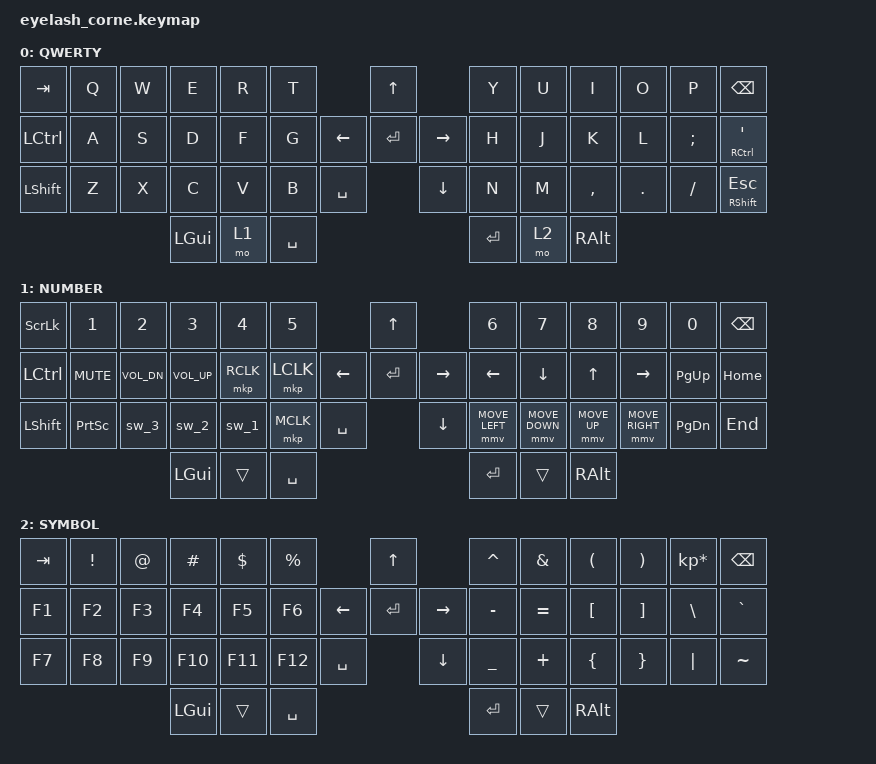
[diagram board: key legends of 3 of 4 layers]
#define ZMK_POINTING_DEFAULT_MOVE_VAL 1200  // 600
#define ZMK_POINTING_DEFAULT_SCRL_VAL 25   // 10

#include <input/processors.dtsi>
#include <zephyr/dt-bindings/input/input-event-codes.h>
#include <behaviors.dtsi>
#include <dt-bindings/zmk/bt.h>
#include <dt-bindings/zmk/ext_power.h>
#include <dt-bindings/zmk/keys.h>
#include <dt-bindings/zmk/outputs.h>
#include <dt-bindings/zmk/pointing.h>
#include <dt-bindings/zmk/rgb.h>

&mmv_input_listener { input-processors = <&zip_xy_scaler 2 1>; };

&msc_input_listener { input-processors = <&zip_scroll_scaler 2 1>; };

&msc {
    acceleration-exponent = <1>;      // 0
    time-to-max-speed-ms = <100>;       // 300
    delay-ms = <0>;                   // 0
};

&mmv {
    time-to-max-speed-ms = <500>;
    acceleration-exponent = <1>;
    trigger-period-ms = <16>;
};


/ {

    macros {
        sw_1: sw_1 {
            compatible = "zmk,behavior-macro";
            label = "SW_1";
             #binding-cells = <0>;
             wait-ms = <40>;
             tap-ms = <40>;
            bindings =
                  <&macro_press &kp LGUI>
                , <&macro_tap &kp SPACE>
                , <&macro_release &kp LGUI>
                , <&macro_tap &kp SEMI>
                , <&macro_press &kp LGUI>
                , <&macro_tap &kp SPACE>
                , <&macro_release &kp LGUI>
                ;
        };

        sw_2: sw_2 {
            compatible = "zmk,behavior-macro";
            label = "SW_2";
             #binding-cells = <0>;
             wait-ms = <40>;
             tap-ms = <40>;
            bindings =
                  <&macro_press &kp LGUI>
                , <&macro_tap &kp SPACE>
                , <&macro_release &kp LGUI>
                , <&macro_tap &kp SQT>
                , <&macro_press &kp LGUI>
                , <&macro_tap &kp SPACE>
                , <&macro_release &kp LGUI>
                ;
        };

        sw_3: sw_3 {
            compatible = "zmk,behavior-macro";
            label = "SW_3";
             #binding-cells = <0>;
             wait-ms = <40>;
             tap-ms = <40>;
            bindings =
                  <&macro_press &kp LGUI>
                , <&macro_tap &kp SPACE>
                , <&macro_release &kp LGUI>
                , <&macro_tap &kp LBKT> 
                , <&macro_press &kp LGUI>
                , <&macro_tap &kp SPACE>
                , <&macro_release &kp LGUI>
                ;
        };
        
    };
    behaviors {
        td0: td0 {
            compatible = "zmk,behavior-tap-dance";
            display-name = "Shift/Caps Lock Tap Dance";
            #binding-cells = <0>;
            bindings = <&kp LEFT_SHIFT>, <&kp CAPS>;
        };
    };

    rgb_encoder: rgb_encoder {
        compatible = "zmk,behavior-sensor-rotate";
        #sensor-binding-cells = <0>;
        bindings = <&rgb_ug RGB_BRI>, <&rgb_ug RGB_BRD>;
    };

    scroll_encoder: scroll_encoder {
        compatible = "zmk,behavior-sensor-rotate";
        #sensor-binding-cells = <0>;
        bindings = <&msc SCRL_DOWN>, <&msc SCRL_UP>;
        tap-ms = <100>;
    };

    keymap {
        compatible = "zmk,keymap";

        default_layer {
            display-name = "QWERTY";
            bindings = <
&kp TAB    &kp Q  &kp W      &kp E     &kp R  &kp T                              &kp UP                &kp Y        &kp U  &kp I      &kp O    &kp P     &kp BSPC
&kp LCTRL  &kp A  &kp S      &kp D     &kp F  &kp G                    &kp LEFT  &kp ENTER  &kp RIGHT  &kp H        &kp J  &kp K      &kp L    &kp SEMI  &mt RCTRL SQT 
&kp LSHFT  &kp Z  &kp X      &kp C     &kp V  &kp B       &kp SPACE              &kp DOWN              &kp N        &kp M  &kp COMMA  &kp DOT  &kp FSLH  &mt RSHIFT ESCAPE
                             &kp LGUI  &mo 1  &kp SPACE                                                &kp RET  &mo 2  &kp RALT
            >;
            sensor-bindings = <&inc_dec_kp C_VOLUME_UP C_VOLUME_DOWN>;
        };

        lower_layer {
            display-name = "NUMBER";
            bindings = <
   &kp SLCK   &kp N1      &kp N2        &kp N3        &kp N4       &kp N5                               &kp UP                   &kp N6           &kp N7          &kp N8        &kp N9           &kp N0         &kp BSPC
   &kp LCTRL  &kp C_MUTE  &kp C_VOL_DN  &kp C_VOL_UP  &mkp RCLK    &mkp LCLK                  &kp LEFT  &kp ENTER  &kp RIGHT     &kp LEFT         &kp DOWN        &kp UP        &kp RIGHT        &kp PAGE_UP    &kp HOME
   &kp LSHFT  &kp PSCRN   &sw_3         &sw_2         &sw_1        &mkp MCLK    &kp SPACE               &kp DOWN                 &mmv MOVE_LEFT   &mmv MOVE_DOWN  &mmv MOVE_UP  &mmv MOVE_RIGHT  &kp PAGE_DOWN  &kp END
                          	            &kp LGUI      &trans       &kp SPACE                                                     &kp RET  &trans  &kp RALT
            >;
            sensor-bindings = <&scroll_encoder>;
        };

        raise_layer {
            display-name = "SYMBOL";
            bindings = <
   &kp  TAB  &kp EXCL &kp AT   &kp HASH  &kp DLLR  &kp PRCNT                          &kp UP                 &kp CARET &kp AMPS  &kp LPAR   &kp RPAR &kp KP_MULTIPLY &kp BSPC
   &kp F1    &kp F2    &kp F3  &kp F4    &kp F5    &kp F6                   &kp LEFT  &kp ENTER  &kp RIGHT   &kp MINUS &kp EQUAL &kp LBKT   &kp RBKT &kp BSLH        &kp GRAVE
   &kp F7    &kp F8    &kp F9  &kp F10   &kp F11   &kp F12     &kp SPACE              &kp DOWN               &kp UNDER &kp PLUS  &kp LBRC   &kp RBRC &kp PIPE        &kp TILDE
                    	         &kp LGUI  &trans    &kp SPACE                                                 &kp RET   &trans    &kp RALT
            >;
            sensor-bindings = <&scroll_encoder>;
        };

        layer_3 {
            display-name = "SETTING";
            bindings = <
&trans  &trans  &trans  &bt BT_CLR  &bt BT_NXT  &bt BT_PRV                &trans           &trans  &trans  &trans  &trans  &trans  &trans
&trans  &trans  &trans  &trans      &trans      &trans             &trans &trans &trans    &trans  &trans  &trans  &trans  &trans  &trans
&trans  &trans  &trans  &trans      &trans      &trans     &trans         &trans           &trans  &trans  &trans  &trans  &trans  &trans
            >;
            sensor-bindings = <&scroll_encoder>;
        };
    };

    conditional_layers {
        compatible = "zmk,conditional-layers";

        Settings {
            if-layers = <1 2>;
            then-layer = <3>;
        };
    };
};
